# K1921VK01T register map
Vendor: NIIET; Series: K1921VKx; File version: 2.2
CPU: CM4 r0p1, little endian, MPU, FPU, 3 interrupt priority bits
Registers are 32-bit, read-write, reset 0x0 unless marked. A register's access mark holds for its fields unless they carry their own. Offsets are from the block's base; [hi:lo] are bit positions.

## NT_USBOTG — USB OTG controller registers
Base 0x80090704
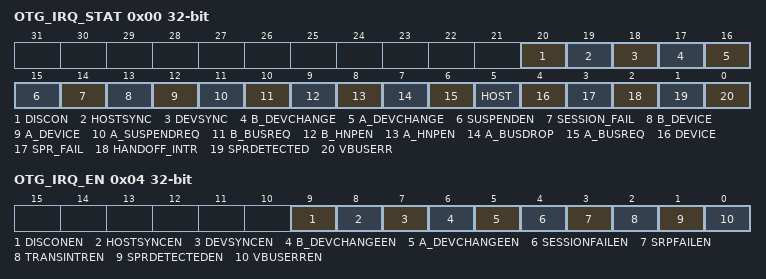
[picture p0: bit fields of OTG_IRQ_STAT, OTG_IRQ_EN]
0x00 OTG_IRQ_STAT — USB OTG interrupt flag register
  [20] DISCON — Bit is set when disconnected not in suspend mode
  [19] HOSTSYNC — When resynchronization host this bit is set and the corresponding interrupt enable bit
  [18] DEVSYNC — When resynchronization device this bit is set and the corresponding interrupt enable bit
  [17] B_DEVCHANGE — Bit is set when you change the display B. Simultaneously, the appropriate interrupt enable bit
  [16] A_DEVCHANGE — Bit is set when there is a change device A. At the same time, the appropriate interrupt enable bit.
  [15] SUSPENDEN — Request
  [14] SESSION_FAIL — Bit is device B, A when the device interrupts the signal Vbus.
  [13] B_DEVICE ro — Display device B connections
  [12] A_DEVICE ro — Display device A connections
  [11] A_SUSPENDREQ — Request A suspension device
  [10] B_BUSREQ — Request bus control device B
  [9] B_HNPEN — Resolution run HNP device A
  [8] A_HNPEN — Resolution run HNP device A
  [7] A_BUSDROP — Set when the device A, you must disconnect bus
  [6] A_BUSREQ — Request A device control bus
  [5] HOST ro — Set when the kernel is running as a host controller
  [4] DEVICE ro — Set when the kernel is running as a device controller
  [3] SPR_FAIL — Indication of lack of response from the host mode operation Device
  [2] HANDOFF_INTR — Interrupt when the output state Id
  [1] SPRDETECTED — Enable interrupt srp_detected
  [0] VBUSERR — Enable interrupt a_clr_err
0x04 OTG_IRQ_EN — Interrupt Enable USB OTG register
  [9] DISCONEN — Enable interrupt Disconnect
  [8] HOSTSYNCEN — Enable interrupt HOSTSYNC (Resynchronization host)
  [7] DEVSYNCEN — Enable interrupt DEVSYNC
  [6] B_DEVCHANGEEN — Enable interrupt B_DEVCHANGE
  [5] A_DEVCHANGEEN — Enable interrupt A_DEVCHANGE
  [4] SESSIONFAILEN — Enable interrupt SESSIONFAIL
  [3] SRPFAILEN — Enable interrupt SRPFAIL
  [2] TRANSINTREN — Enable interrupt TRANSINTR
  [1] SPRDETECTEDEN — Enable interrupt SPRDETECTED
  [0] VBUSERREN — Enable interrupt VBUSERR

## NT_WDT — Watchdog controller registers
Base 0xA0000000
0x00 LOAD — Watchdog Load Register
  [31:0] COUNT
0x04 VALUE ro — Watchdog Value Register
  [31:0] WDTVAL
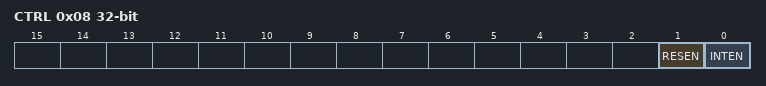
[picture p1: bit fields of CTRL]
0x08 CTRL — Watchdog Control Register
  [1] RESEN — Enable watchdog reset output
  [0] INTEN — Enable the interrupt event
0x0C INTCLR wo — Watchdog Clear Interrupt Register
  [31:0] WDTCLR
0x10 RIS ro — Watchdog Raw Interrupt Status Register
  [0] RAWWDTINT — Raw interrupt status from the counter
0x14 MIS ro — Watchdog Interrupt Status Register
  [0] WDTINT — Enabled interrupt status from the counter
0xC00 LOCK wo — Watchdog Lock Register
  [0] REG_WR_DIS — Disable write access to all registers

## NT_I2C0 — I2C controller registers
Base 0xA0001000
Same registers: NT_I2C1 0xA0002000
0x00 SDA — Data register
  [7:0] DATA
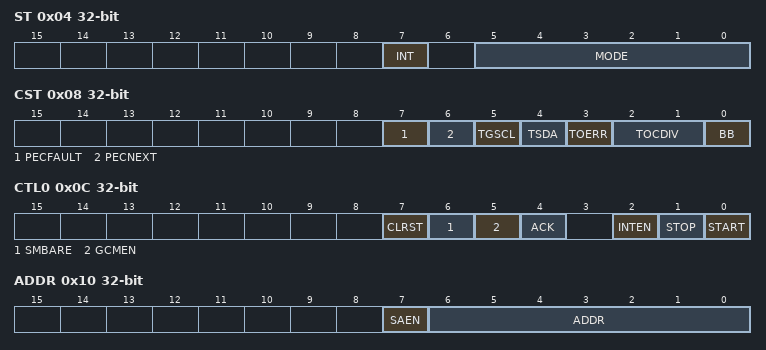
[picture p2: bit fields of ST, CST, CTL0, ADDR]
0x04 ST — Status register
  [7] INT — Interrupt flag
  [5:0] MODE
0x08 CST — Status and control register
  [7] PECFAULT — Error flag
  [6] PECNEXT — Bit control transmit CRC
  [5] TGSCL — Bit switch SCL
  [4] TSDA — Bit test SDA
  [3] TOERR — Flag error simple bus
  [2:1] TOCDIV
    0=disable clock; 1=Div4 (clock divided by 4); 2=Div8 (clock divided by 8); 3=Div16 (clock divided by 16)
  [0] BB — Flag employment bus
0x0C CTL0 — Control register 0
  [7] CLRST — Bit reset flag interrupt
  [6] SMBARE — Control bit part a response to the response address
  [5] GCMEN — Control bit part a response to the general call address
  [4] ACK — Acknowledgment bit reception
  [2] INTEN — Interrupt enable bit
  [1] STOP — Stop bit
  [0] START — Start bit
0x10 ADDR — Register own address
  [7] SAEN — Enable bit address recognition
  [6:0] ADDR
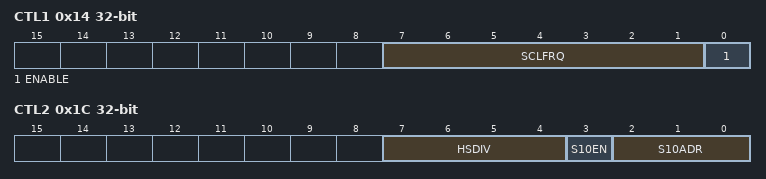
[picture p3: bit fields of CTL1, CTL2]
0x14 CTL1 — Control register 1
  [7:1] SCLFRQ
  [0] ENABLE — Enable I2C
0x18 TOPR — Prescaler load register
  [7:0] SMBTOPR
0x1C CTL2 — Control register 2
  [7:4] HSDIV
  [3] S10EN — Bit enabled 10-bit addressing slave
  [2:0] S10ADR
